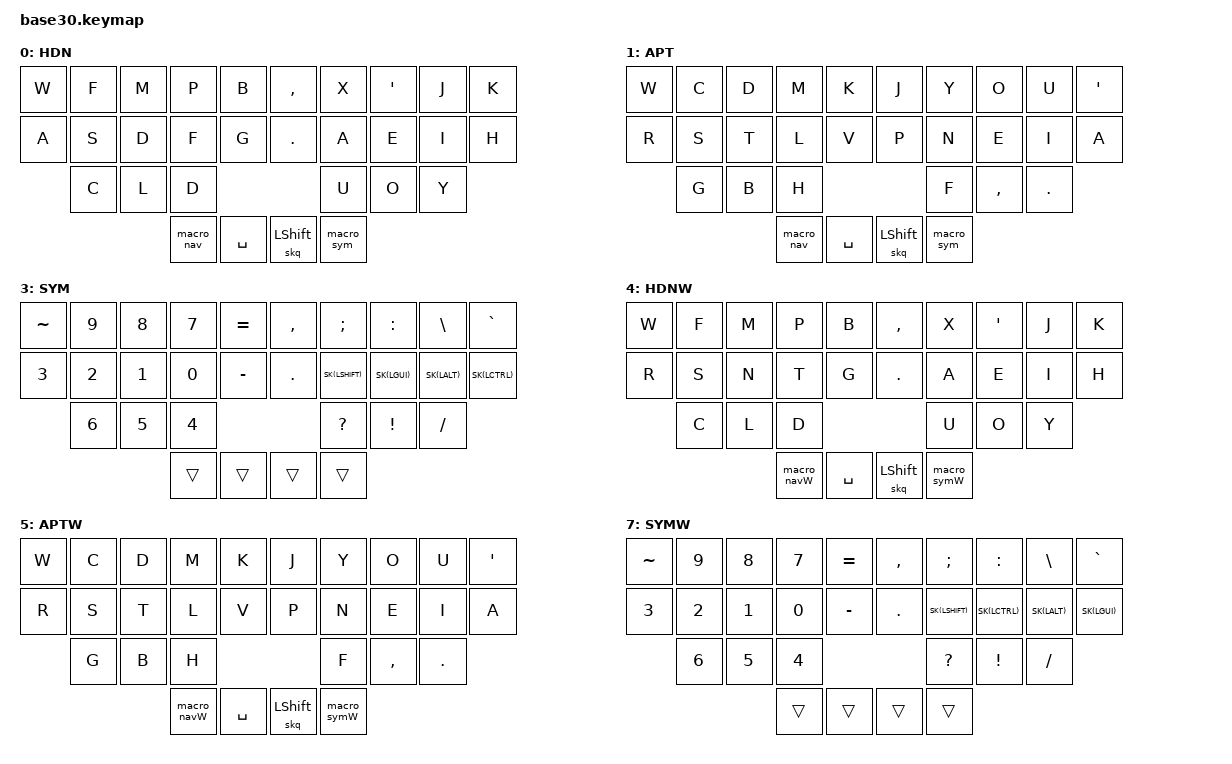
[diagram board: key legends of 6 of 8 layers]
/*
 * Copyright (c) 2020 The ZMK Contributors
 *
 * SPDX-License-Identifier: MIT
 */

#include <behaviors.dtsi>
#include <dt-bindings/zmk/keys.h>
#include <dt-bindings/zmk/bt.h>
#include <dt-bindings/zmk/outputs.h>

#define HDN 0
#define APT 1
#define NAV 2
#define SYM 3
#define HDNW 4
#define APTW 5
#define NAVW 6
#define SYMW 7

#define SK(KEY) &nk KEY KEY

&sk {
  release-after-ms = <60000>;
};

&caps_word {
  continue-list = <UNDERSCORE MINUS BACKSPACE K_CANCEL>;
};

/*                KEY POSITIONS

  ╭────────────────────╮ ╭────────────────────╮
  │  0   1   2   3   4 │ │  5   6   7   8   9 │
  │ 10  11  12  13  14 │ │ 15  16  17  18  19 │
  │     20  21  22     │ │     23  24  25     │
  ╰───────────╮ 26  27 │ │ 28  29 ╭───────────╯
              ╰────────╯ ╰────────╯            */

/ {

  behaviors {

    // Sticky key on tap, normal key on hold
    // Useful for modifier-clicking without the modifier remaining active
    nk: not_so_sticky_key {
        compatible = "zmk,behavior-hold-tap";
        label = "NOT_SO_STICKY_KEY";
        #binding-cells = <2>;
        tapping_term_ms = <250>;
        flavor = "tap-preferred";
        bindings = <&kp>, <&sk>;
    };

    skq: sticky_key_quick_release {
      compatible = "zmk,behavior-sticky-key";
      label = "STICKY_KEY_QUICK_RELEASE";
      #binding-cells = <1>;
      bindings = <&kp>;
      quick-release;
      release-after-ms = <750>;
    };

    lal: layer-alpha {
        compatible = "zmk,behavior-hold-tap";
        label = "LAYER_ALPHA";
        #binding-cells = <2>;
        flavor = "balanced";
        tapping-term-ms = <170>;
        quick-tap-ms = <100>;
        global-quick-tap;
        bindings = <&mo>, <&kp>;
    };

    combos {
          #include "combos30.dtsi"
     };
    macros {
          #include "macros.dtsi"
     };
  };
 
        keymap {
                compatible = "zmk,keymap";
 
        hands_down {
            label = "HDN";
            bindings = <
// ╭─────────────┬─────────────┬─────────────┬─────────────┬─────────────╮   ╭─────────────┬─────────────┬─────────────┬─────────────┬─────────────╮
     &kp W         &kp F         &kp M         &kp P         &kp B             &kp COMMA     &kp X         &kp SQT       &kp J         &kp K
     &kp A         &kp S         &kp D         &kp F         &kp G             &kp DOT       &kp A         &kp E         &kp I         &kp H
                   &kp C         &kp L         &kp D                                         &kp U         &kp O         &kp Y
//               ╰─────────────┴─────────────┼─────────────┤                               ├─────────────┼─────────────┴─────────────╯
                                               &macro_nav   &kp SPACE          &skq LSHIFT    &macro_sym
//                                           ╰─────────────┴─────────────╯   ╰─────────────┴─────────────╯
            >;
        };

        apt {
            label = "APT";
            bindings = <
// ╭─────────────┬─────────────┬─────────────┬─────────────┬─────────────╮   ╭─────────────┬─────────────┬─────────────┬─────────────┬─────────────╮
     &kp W         &kp C         &kp D         &kp M         &kp K             &kp J         &kp Y         &kp O         &kp U         &kp SQT
// ├──── ─────────┼─────────────┼─────────────┼─────────────┼─────────────┤   ├─────────────┼─────────────┼─────────────┼─────────────┼─────────────┤
     &kp R         &kp S         &kp T         &kp L         &kp V             &kp P         &kp N         &kp E         &kp I         &kp A     
// ├─────────────┼─────────────┼─────────────┼─────────────┼─────────────┤   ├─────────────┼─────────────┼─────────────┼─────────────┼─────────────┤
                   &kp G         &kp B         &kp H                                         &kp F         &kp COMMA     &kp DOT
//               ╰─────────────┴─────────────┼─────────────┤                               ├─────────────┼─────────────┴─────────────╯
                                               &macro_nav   &kp SPACE          &skq LSHIFT    &macro_sym
//                                           ╰─────────────┴─────────────╯   ╰─────────────┴─────────────╯
            >;
        };

        navigation {
            label = "NAV";
            bindings = <
// ╭─────────────┬─────────────┬─────────────┬─────────────┬─────────────╮   ╭─────────────┬─────────────┬─────────────┬─────────────┬─────────────╮
  &kp LC(LA(LS(P)))    &kp ENTER     &kp BACKSPACE  &kp TAB     &kp DELETE      &kp LA(BACKSPACE) &none         &kp UP        &kp LG(Q)  &kp LA(LC(LS(LG(K))))
     SK(LCTRL)         SK(LALT)      SK(LGUI)       SK(LSHIFT)  &kp LG(A)       &kp LG(A)         &kp LEFT      &kp DOWN      &kp RIGHT  &kp LA(LC(LS(LG(Y))))
                       &kp LG(X)     &kp LG(C)      &kp LG(V)                                     &kp ENTER     &kp BACKSPACE &kp TAB
//               ╰─────────────┴─────────────┼─────────────┤                               ├─────────────┼─────────────┴─────────────╯
                                                &trans        &trans            &trans       &trans
//                                           ╰─────────────┴─────────────╯   ╰─────────────┴─────────────╯
            >;
        };

        symbols {
            label = "SYM";
            bindings = <
// ╭─────────────┬─────────────┬─────────────┬─────────────┬─────────────╮   ╭─────────────┬─────────────┬─────────────┬─────────────┬─────────────╮
     &kp TILDE     &kp N9       &kp N8         &kp N7         &kp EQUAL         &kp COMMA    &kp SEMI      &kp COLON    &kp BSLH      &kp GRAVE
     &kp N3        &kp N2       &kp N1         &kp N0         &kp MINUS         &kp DOT      SK(LSHIFT)    SK(LGUI)     SK(LALT)      SK(LCTRL)
                   &kp N6       &kp N5         &kp N4                                        &kp QMARK     &kp EXCL     &kp SLASH
//               ╰─────────────┴─────────────┼─────────────┤                               ├─────────────┼─────────────┴─────────────╯
                                               &trans         &trans            &trans        &trans
//                                           ╰─────────────┴─────────────╯   ╰─────────────┴─────────────╯
            >;
        };

        hands_down_windows {
            label = "HDNW";
            bindings = <
// ╭─────────────┬─────────────┬─────────────┬─────────────┬─────────────╮   ╭─────────────┬─────────────┬─────────────┬─────────────┬─────────────╮
     &kp W         &kp F         &kp M         &kp P         &kp B             &kp COMMA     &kp X         &kp SQT       &kp J         &kp K
     &kp R         &kp S         &kp N         &kp T         &kp G             &kp DOT       &kp A         &kp E         &kp I         &kp H
                   &kp C         &kp L         &kp D                                         &kp U         &kp O         &kp Y
//               ╰─────────────┴─────────────┼─────────────┤                               ├─────────────┼─────────────┴─────────────╯
                                               &macro_navW  &kp SPACE          &skq LSHIFT   &macro_symW
//                                           ╰─────────────┴─────────────╯   ╰─────────────┴─────────────╯
            >;
        };
        
        aptw {
            label = "APTW";
            bindings = <
// ╭─────────────┬─────────────┬─────────────┬─────────────┬─────────────╮   ╭─────────────┬─────────────┬─────────────┬─────────────┬─────────────╮
     &kp W         &kp C         &kp D         &kp M         &kp K             &kp J         &kp Y         &kp O         &kp U         &kp SQT
// ├──── ─────────┼─────────────┼─────────────┼─────────────┼─────────────┤   ├─────────────┼─────────────┼─────────────┼─────────────┼─────────────┤
     &kp R         &kp S         &kp T         &kp L         &kp V             &kp P         &kp N         &kp E         &kp I         &kp A     
// ├─────────────┼─────────────┼─────────────┼─────────────┼─────────────┤   ├─────────────┼─────────────┼─────────────┼─────────────┼─────────────┤
                   &kp G         &kp B         &kp H                                         &kp F         &kp COMMA     &kp DOT
//               ╰─────────────┴─────────────┼─────────────┤                               ├─────────────┼─────────────┴─────────────╯
                                               &macro_navW  &kp SPACE          &skq LSHIFT   &macro_symW
//                                           ╰─────────────┴─────────────╯   ╰─────────────┴─────────────╯
            >;
        };

        navigation_windows {
            label = "NAVW";
            bindings = <
// ╭─────────────┬─────────────┬─────────────┬─────────────┬─────────────╮   ╭─────────────┬─────────────┬─────────────┬─────────────┬─────────────╮
&kp LC(LA(LS(P)))  &kp ENTER     &kp BACKSPACE  &kp TAB      &kp DELETE        &kp LC(BACKSPACE)  &kp F2        &kp UP        &kp LA(F4)    &none
     SK(LGUI)      SK(LALT)      SK(LCTRL)      SK(LSHIFT)   &kp LC(A)         &kp LC(A)          &kp LEFT      &kp DOWN      &kp RIGHT     &none
                   &kp LC(X)     &kp LC(C)      &kp LC(V)                                         &kp ENTER     &kp BACKSPACE &kp TAB
//               ╰─────────────┴─────────────┼─────────────┤                               ├─────────────┼─────────────┴─────────────╯
                                                &trans          &trans         &trans        &trans
//                                           ╰─────────────┴─────────────╯   ╰─────────────┴─────────────╯
            >;
        };

        symbols_windows {
            label = "SYMW";
            bindings = <
// ╭─────────────┬─────────────┬─────────────┬─────────────┬─────────────╮   ╭─────────────┬─────────────┬─────────────┬─────────────┬─────────────╮
     &kp TILDE     &kp N9       &kp N8         &kp N7         &kp EQUAL         &kp COMMA    &kp SEMI      &kp COLON    &kp BSLH      &kp GRAVE
     &kp N3        &kp N2       &kp N1         &kp N0         &kp MINUS         &kp DOT      SK(LSHIFT)    SK(LCTRL)    SK(LALT)      SK(LGUI)
                   &kp N6       &kp N5         &kp N4                                        &kp QMARK     &kp EXCL     &kp SLASH
//               ╰─────────────┴─────────────┼─────────────┤                               ├─────────────┼─────────────┴─────────────╯
                                               &trans        &trans            &trans        &trans
//                                           ╰─────────────┴─────────────╯   ╰─────────────┴─────────────╯
            >;
        };
  };

};
